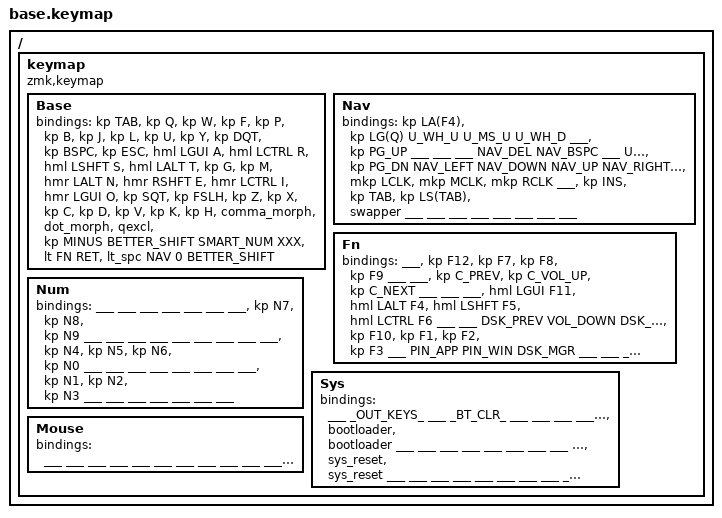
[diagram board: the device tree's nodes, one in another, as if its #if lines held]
/*
 * Shared base keymap for 42-key Corne (6x3+3)
 * Features: Colemak-DH, timeless homerow mods, combos, smart layers
 *
 * Board-specific keymaps should:
 *   1. #define CONFIG_WIRELESS (if applicable)
 *   2. #include the appropriate key-labels header
 *   3. #include "base.keymap"
 */

#include <behaviors.dtsi>
#include <behaviors/num_word.dtsi> // Requires zmk-auto-layer module.
#include <behaviors/unicode.dtsi> // Requires zmk-unicode module.
#include <zmk-helpers/helper.h> // Requires zmk-helpers module.
#include <dt-bindings/zmk/keys.h>

#ifdef CONFIG_WIRELESS
  #include <dt-bindings/zmk/bt.h>
  #include <dt-bindings/zmk/outputs.h>
  #define _BT_SEL_KEYS_                                                          \
      &bt BT_SEL 0 &bt BT_SEL 1 &bt BT_SEL 2 &bt BT_SEL 3
  #define _OUT_KEYS_                                                             \
      &out OUT_TOG  &out OUT_USB  &out OUT_BLE
  #define _BT_CLR_ &bt BT_CLR
#else
  #define _BT_SEL_KEYS_ &trans &trans &trans &trans
  #define _OUT_KEYS_    &trans &trans &trans
  #define _BT_CLR_      &trans
#endif

#include "settings.dtsi"
#include "behaviors.dtsi"

/* Combos, leader key sequences, mouse emulation */

// Combos must be sourced after behaviors.dtsi
#include "combos_horizontal.dtsi"
#include "combos_vertical.dtsi"
#include "leader.dtsi"
#include "mouse.dtsi"

/* Keymap */

ZMK_CONDITIONAL_LAYER(sys, FN NUM, SYS) // FN + NUM --> SYS.

/ {
    keymap {
        compatible = "zmk,keymap";

        Base {
// ╭─────────────┬─────────────┬─────────────┬─────────────┬─────────────┬─────────────╮ ╭─────────────┬─────────────┬─────────────┬─────────────┬─────────────┬─────────────╮
//    Tab           Q             W             F             P             B                J             L             U             Y             "             Bspc
// ├─────────────┼─────────────┼─────────────┼─────────────┼─────────────┼─────────────┤ ├─────────────┼─────────────┼─────────────┼─────────────┼─────────────┼─────────────┤
//    Esc           A/GUI         R/Ctrl        S/Shft        T/Alt         G                M             N/Alt         E/Shft        I/Ctrl        O/GUI         '
// ├─────────────┼─────────────┼─────────────┼─────────────┼─────────────┼─────────────┤ ├─────────────┼─────────────┼─────────────┼─────────────┼─────────────┼─────────────┤
//    /             Z             X             C             D             V                K             H             , morph       . morph       ?!            -
// ╰─────────────┴─────────────┴─────────────┼─────────────┼─────────────┼─────────────┤ ├─────────────┼─────────────┼─────────────┼─────────────┴─────────────┴─────────────╯
//                                              Magic Shift   Smart Num     (none)           Enter/Fn      Space/Nav     Magic Shift
//                                           ╰─────────────┴─────────────┴─────────────╯ ╰─────────────┴─────────────┴─────────────╯
            bindings = <
   &kp TAB       &kp Q         &kp W         &kp F         &kp P         &kp B             &kp J         &kp L         &kp U         &kp Y         &kp DQT       &kp BSPC
   &kp ESC       &hml LGUI A   &hml LCTRL R  &hml LSHFT S  &hml LALT T   &kp G             &kp M         &hmr LALT N   &hmr RSHFT E  &hmr LCTRL I  &hmr LGUI O   &kp SQT
   &kp FSLH      &kp Z         &kp X         &kp C         &kp D         &kp V             &kp K         &kp H         &comma_morph  &dot_morph    &qexcl        &kp MINUS
                                             BETTER_SHIFT  SMART_NUM     XXX               &lt FN RET    &lt_spc NAV 0 BETTER_SHIFT
            >;
        };

        Nav {
// ╭─────────────┬─────────────┬─────────────┬─────────────┬─────────────┬─────────────╮ ╭─────────────┬─────────────┬─────────────┬─────────────┬─────────────┬─────────────╮
//    &kp LA(F4)    &kp LGUI(Q)   Wheel Up      Mouse Up      Wheel Down    ---              PgUp          ___           ___           ___           Del²word      Bspc²word
// ├─────────────┼─────────────┼─────────────┼─────────────┼─────────────┼─────────────┤ ├─────────────┼─────────────┼─────────────┼─────────────┼─────────────┼─────────────┤
//    ___           Wheel Left    Mouse Left    Mouse Down    Mouse Right   Wheel Right      PgDn          Left/WdLeft   Down/PgDn     Up/PgUp       Right/WdRight ___
// ├─────────────┼─────────────┼─────────────┼─────────────┼─────────────┼─────────────┤ ├─────────────┼─────────────┼─────────────┼─────────────┼─────────────┼─────────────┤
//    ___           ___           Left Click    Mid Click     Right Click   ___              Insert        Tab           Shift+Tab     Swapper       ___           ___
// ╰─────────────┴─────────────┴─────────────┼─────────────┼─────────────┼─────────────┤ ├─────────────┼─────────────┼─────────────┼─────────────┴─────────────┴─────────────╯
//                                              ___           ___           ___              ___           ___           ___
//                                           ╰─────────────┴─────────────┴─────────────╯ ╰─────────────┴─────────────┴─────────────╯
            bindings = <
   &kp LA(F4)    &kp LG(Q)     U_WH_U        U_MS_U        U_WH_D        ___               &kp PG_UP     ___           ___           ___           NAV_DEL       NAV_BSPC
   ___           U_WH_L        U_MS_L        U_MS_D        U_MS_R        U_WH_R            &kp PG_DN     NAV_LEFT      NAV_DOWN      NAV_UP        NAV_RIGHT     ___
   ___           ___           &mkp LCLK     &mkp MCLK     &mkp RCLK     ___               &kp INS       &kp TAB       &kp LS(TAB)   &swapper      ___           ___
                                             ___           ___           ___               ___           ___           ___
            >;
        };

        Fn {
// ╭─────────────┬─────────────┬─────────────┬─────────────┬─────────────┬─────────────╮ ╭─────────────┬─────────────┬─────────────┬─────────────┬─────────────┬─────────────╮
//    ___           F12           F7            F8            F9            ___              ___           Prev Track    Vol Up        Next Track    ___           ___
// ├─────────────┼─────────────┼─────────────┼─────────────┼─────────────┼─────────────┤ ├─────────────┼─────────────┼─────────────┼─────────────┼─────────────┼─────────────┤
//    ___           F11/GUI       F4/Alt        F5/Shft       F6/Ctrl       ___              ___           Desk Prev     Vol Down      Desk Next     ___           ___
// ├─────────────┼─────────────┼─────────────┼─────────────┼─────────────┼─────────────┤ ├─────────────┼─────────────┼─────────────┼─────────────┼─────────────┼─────────────┤
//    ___           F10           F1            F2            F3            ___              Pin App       Pin Win       Desk Mgr      ___           ___           ___
// ╰─────────────┴─────────────┴─────────────┼─────────────┼─────────────┼─────────────┤ ├─────────────┼─────────────┼─────────────┼─────────────┴─────────────┴─────────────╯
//                                              ___           ___           ___              Mute          Play/Pause    ___
//                                           ╰─────────────┴─────────────┴─────────────╯ ╰─────────────┴─────────────┴─────────────╯
            bindings = <
   ___           &kp F12       &kp F7        &kp F8        &kp F9        ___               ___           &kp C_PREV    &kp C_VOL_UP  &kp C_NEXT    ___           ___
   ___           &hml LGUI F11 &hml LALT F4  &hml LSHFT F5 &hml LCTRL F6 ___               ___           DSK_PREV      VOL_DOWN      DSK_NEXT      ___           ___
   ___           &kp F10       &kp F1        &kp F2        &kp F3        ___               PIN_APP       PIN_WIN       DSK_MGR       ___           ___           ___
                                             ___           ___           ___               ___           ___           ___
            >;
        };

        Num {
// ╭─────────────┬─────────────┬─────────────┬─────────────┬─────────────┬─────────────╮ ╭─────────────┬─────────────┬─────────────┬─────────────┬─────────────┬─────────────╮
//    ___           ___           ^             $             %             ___              ___           7             8             9             ___           ___
// ├─────────────┼─────────────┼─────────────┼─────────────┼─────────────┼─────────────┤ ├─────────────┼─────────────┼─────────────┼─────────────┼─────────────┼─────────────┤
//    ___           /             *             -             +             ___              ___           4             5             6             0             ___
// ├─────────────┼─────────────┼─────────────┼─────────────┼─────────────┼─────────────┤ ├─────────────┼─────────────┼─────────────┼─────────────┼─────────────┼─────────────┤
//    ___           ___           ___           ,             .             ___              ___           1             2             3             ___           ___
// ╰─────────────┴─────────────┴─────────────┼─────────────┼─────────────┼─────────────┤ ├─────────────┼─────────────┼─────────────┼─────────────┴─────────────┴─────────────╯
//                                              ___           ___           ___              ___           =             ___
//                                           ╰─────────────┴─────────────┴─────────────╯ ╰─────────────┴─────────────┴─────────────╯
            bindings = <
   ___           ___           ___           ___           ___           ___               ___           &kp N7        &kp N8        &kp N9        ___           ___
   ___           ___           ___           ___           ___           ___               ___           &kp N4        &kp N5        &kp N6        &kp N0        ___
   ___           ___           ___           ___           ___           ___               ___           &kp N1        &kp N2        &kp N3        ___
                                             ___           ___           ___               ___           ___           ___
            >;
        };

        Sys {
// ╭─────────────┬─────────────┬─────────────┬─────────────┬─────────────┬─────────────╮ ╭─────────────┬─────────────┬─────────────┬─────────────┬─────────────┬─────────────╮
//    ___           BT0           BT1           BT2           BT3           BT Clear         ___           ___           ___           ___           ___           ___
// ├─────────────┼─────────────┼─────────────┼─────────────┼─────────────┼─────────────┤ ├─────────────┼─────────────┼─────────────┼─────────────┼─────────────┼─────────────┤
//    ___           OUT_TOG       OUT_USB       OUT_BLE       ___           Bootloader       Bootloader    ___           ___           ___           ___           ___
// ├─────────────┼─────────────┼─────────────┼─────────────┼─────────────┼─────────────┤ ├─────────────┼─────────────┼─────────────┼─────────────┼─────────────┼─────────────┤
//    ___           ___           ___           ___           ___           Reset            Reset         ___           ___           ___           ___           ___
// ╰─────────────┴─────────────┴─────────────┼─────────────┼─────────────┼─────────────┤ ├─────────────┼─────────────┼─────────────┼─────────────┴─────────────┴─────────────╯
//                                              ___           ___           ___              ___           ___           ___
//                                           ╰─────────────┴─────────────┴─────────────╯ ╰─────────────┴─────────────┴─────────────╯
            bindings = <
   ___           _OUT_KEYS_                                ___           _BT_CLR_          ___           ___           ___           ___           ___           ___
   ___           _BT_SEL_KEYS_                                           &bootloader       &bootloader   ___           ___           ___           ___           ___
   ___           ___           ___           ___           ___           &sys_reset        &sys_reset    ___           ___           ___           ___           ___
                                             ___           ___           ___               ___           ___           ___
            >;
        };

        Mouse {
// ╭─────────────┬─────────────┬─────────────┬─────────────┬─────────────┬─────────────╮ ╭─────────────┬─────────────┬─────────────┬─────────────┬─────────────┬─────────────╮
//    ___           ___           ___           ___           ___           ___              ___           ___          Mouse Up       ___           ___           ___
// ├─────────────┼─────────────┼─────────────┼─────────────┼─────────────┼─────────────┤ ├─────────────┼─────────────┼─────────────┼─────────────┼─────────────┼─────────────┤
//    ___           ___           ___           ___           ___           ___              Wheel Left    Mouse Left    Mouse Down    Mouse Right   Wheel Right   ___
// ├─────────────┼─────────────┼─────────────┼─────────────┼─────────────┼─────────────┤ ├─────────────┼─────────────┼─────────────┼─────────────┼─────────────┼─────────────┤
//    ___           ___           ___           ___           ___           ___              ___           Left Click    Mid Click     Right Click   ___           ___
// ╰─────────────┴─────────────┴─────────────┼─────────────┼─────────────┼─────────────┤ ├─────────────┼─────────────┼─────────────┼─────────────┴─────────────┴─────────────╯
//                                              ___           ___           ___              Wheel Up      Wheel Down    ___
//                                           ╰─────────────┴─────────────┴─────────────╯ ╰─────────────┴─────────────┴─────────────╯
            bindings = <
   ___           ___           ___           ___           ___           ___               ___           ___           ___           ___           ___           ___
   ___           ___           ___           ___           ___           ___               ___           ___           ___           ___           ___           ___
                 ___           ___           ___           ___           ___               ___           ___           ___           ___           ___           ___
                                             ___           ___           ___               ___           ___        ___
            >;
        };
    };
};

/* vim: set ft=c tw=174: */
